# Cortex_M7 register map
Vendor: Arm Ltd.; Series: ARMv7E-M; File version: 1.0.0
CPU: CM7 r0p0, little endian, MPU, FPU, double-precision FPU, DSP, 8 interrupt priority bits
Registers are 32-bit, read-write, reset 0x0 unless marked. A register's access mark holds for its fields unless they carry their own. Offsets are from the block's base; [hi:lo] are bit positions; {n}, {i} and the like mark numbered series.

## FPB — Flash Patch and Breakpoint unit (FPBv1): up to eight instruction address comparators for hardware breakpoints or flash patching, and up to eight literal comparators for remapping loads from code space into SRAM.
Base 0xE0002000
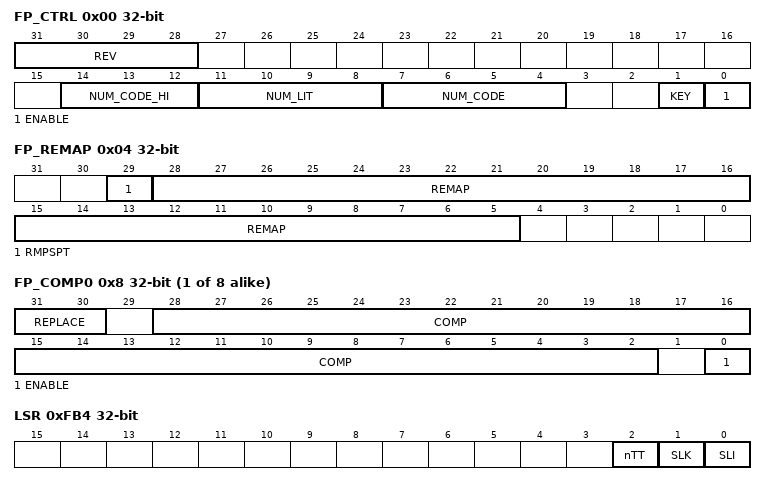
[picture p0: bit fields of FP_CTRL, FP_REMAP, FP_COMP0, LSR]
0x00 FP_CTRL — Flash Patch Control Register: enable, and the number of comparators implemented. Writes must set KEY.
  [31:28] REV — Flash Patch and Breakpoint unit architecture revision: 0 = FPBv1 (ARMv7-M), 1 = FPBv2 (ARMv8-M).
  [14:12] NUM_CODE_HI — Number of instruction address comparators, bits [6:4].
  [11:8] NUM_LIT — Number of literal (data) address comparators; these are the last NUM_LIT comparators.
  [7:4] NUM_CODE — Number of instruction address comparators, bits [3:0] (with NUM_CODE_HI). Reads as zero if there are none.
  [1] KEY — Write 1 to enable writes to FP_CTRL; reads as zero. A write with KEY = 0 is ignored.
  [0] ENABLE — Flash Patch unit enable: 1 = breakpoint and remap comparators active. Reset value 0.
0x04 FP_REMAP — Flash Patch Remap Register: base address in SRAM of the remap table used when a comparator is set to remap (REPLACE = 0).
  [29] RMPSPT — Remap supported: 1 = the FPB supports flash patch remapping, 0 = breakpoints only.
  [28:5] REMAP — Bits [28:5] of the remap base address; bits [31:29] are fixed at 0b001 (SRAM region). The table holds 8-word-aligned replacement words.
{0x8+4i} FP_COMP{i} (i=0..7) — Flash Patch Comparator Register n: address to match (code region, word aligned) and what happens on a match. The first NUM_CODE comparators match instruction fetches, the following NUM_LIT match literal loads.
  [31:30] REPLACE — Instruction comparators: 0 remap to the FP_REMAP table, 1 breakpoint on the lower halfword, 2 breakpoint on the upper halfword, 3 breakpoint on both halfwords. Literal comparators: must be 0 (remap).
  [28:2] COMP — Bits [28:2] of the address to compare (code region 0x00000000-0x1FFFFFFF).
  [0] ENABLE — Comparator enable.
0xFB0 LAR wo — Lock Access Register: write 0xC5ACCE55 to unlock the component for software (not debugger) writes.
  [31:0] KEY — Write 0xC5ACCE55 to unlock, any other value to lock.
0xFB4 LSR ro — Lock Status Register.
  [2] nTT — Not thirty-two bit: 0 = the lock register is 32-bit.
  [1] SLK — Software lock status: 1 = locked, writes from software are ignored.
  [0] SLI — Software lock implemented.
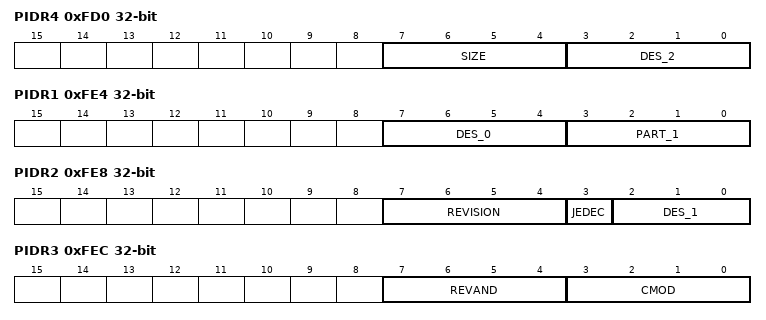
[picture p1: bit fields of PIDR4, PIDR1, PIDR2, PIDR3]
0xFD0 PIDR4 ro — Peripheral Identification Register 4: JEP106 continuation code and component size.
  [7:4] SIZE — Log2 of the number of 4 KB blocks the component occupies (0 = one block).
  [3:0] DES_2 — JEP106 continuation code of the designer (Arm: 0x4).
{0xFC0+4i} PIDR{i} ro (i=5..7) — Peripheral Identification Register {i} (reserved, reads as zero).
0xFE0 PIDR0 ro — Peripheral Identification Register 0: part number bits [7:0].
  [7:0] PART_0 — Part number bits [7:0].
0xFE4 PIDR1 ro — Peripheral Identification Register 1: part number bits [11:8] and designer bits [3:0].
  [7:4] DES_0 — JEP106 identity code bits [3:0] of the designer.
  [3:0] PART_1 — Part number bits [11:8].
0xFE8 PIDR2 ro — Peripheral Identification Register 2: designer bits [6:4], JEDEC flag and revision.
  [7:4] REVISION — Component major revision.
  [3] JEDEC — Always 1: the designer ID is a JEDEC JEP106 code.
  [2:0] DES_1 — JEP106 identity code bits [6:4] of the designer.
0xFEC PIDR3 ro — Peripheral Identification Register 3: customer modified and minor revision.
  [7:4] REVAND — Minor revision (metal fix) number.
  [3:0] CMOD — Customer Modified: 0 if the component has not been modified by the integrator.
0xFF0 CIDR0 ro — Component Identification Register 0: preamble byte 0 (0x0D).
  [7:0] PRMBL_0 — Preamble, reads as 0x0D.
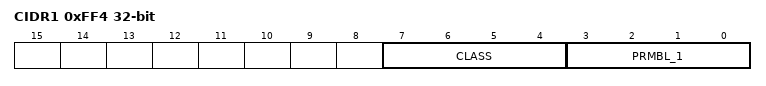
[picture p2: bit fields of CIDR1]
0xFF4 CIDR1 ro — Component Identification Register 1: component class and preamble.
  [7:4] CLASS — Component class: 0x1 ROM table, 0x9 CoreSight component, 0xE generic IP, 0xF CoreLink/PrimeCell.
  [3:0] PRMBL_1 — Preamble, reads as 0x0.
0xFF8 CIDR2 ro — Component Identification Register 2: preamble byte 2 (0x05).
  [7:0] PRMBL_2 — Preamble, reads as 0x05.
0xFFC CIDR3 ro — Component Identification Register 3: preamble byte 3 (0xB1).
  [7:0] PRMBL_3 — Preamble, reads as 0xB1.
